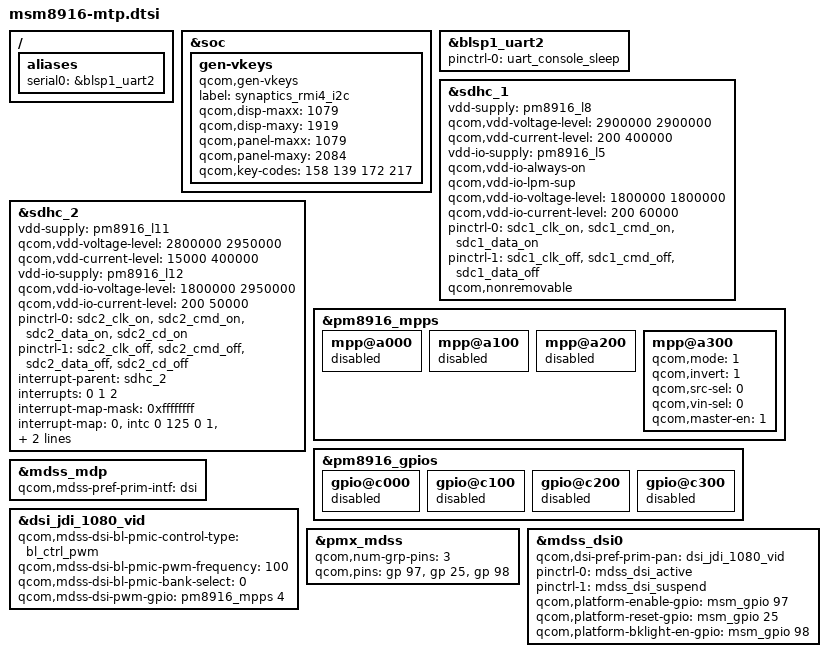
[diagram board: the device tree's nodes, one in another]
/* Copyright (c) 2014, The Linux Foundation. All rights reserved.
 *
 * This program is free software; you can redistribute it and/or modify
 * it under the terms of the GNU General Public License version 2 and
 * only version 2 as published by the Free Software Foundation.
 *
 * This program is distributed in the hope that it will be useful,
 * but WITHOUT ANY WARRANTY; without even the implied warranty of
 * MERCHANTABILITY or FITNESS FOR A PARTICULAR PURPOSE.  See the
 * GNU General Public License for more details.
 */

#include "msm8916.dtsi"
#include "msm8916-pinctrl.dtsi"

/ {
	aliases {
		serial0 = &blsp1_uart2;
	};
};

&soc {
	gen-vkeys {
		compatible = "qcom,gen-vkeys";
		label = "synaptics_rmi4_i2c";
		qcom,disp-maxx = <1079>;
		qcom,disp-maxy = <1919>;
		qcom,panel-maxx = <1079>;
		qcom,panel-maxy = <2084>;
		qcom,key-codes = <158 139 172 217>;
	};
};

&blsp1_uart2 {
	status = "ok";
	pinctrl-names = "default";
	pinctrl-0 = <&uart_console_sleep>;
};

&sdhc_1 {
	vdd-supply = <&pm8916_l8>;
	qcom,vdd-voltage-level = <2900000 2900000>;
	qcom,vdd-current-level = <200 400000>;

	vdd-io-supply = <&pm8916_l5>;
	qcom,vdd-io-always-on;
	qcom,vdd-io-lpm-sup;
	qcom,vdd-io-voltage-level = <1800000 1800000>;
	qcom,vdd-io-current-level = <200 60000>;

	pinctrl-names = "active", "sleep";
	pinctrl-0 = <&sdc1_clk_on &sdc1_cmd_on &sdc1_data_on>;
	pinctrl-1 = <&sdc1_clk_off &sdc1_cmd_off &sdc1_data_off>;

	qcom,nonremovable;

	status = "ok";
};

&sdhc_2 {
	vdd-supply = <&pm8916_l11>;
	qcom,vdd-voltage-level = <2800000 2950000>;
	qcom,vdd-current-level = <15000 400000>;

	vdd-io-supply = <&pm8916_l12>;
	qcom,vdd-io-voltage-level = <1800000 2950000>;
	qcom,vdd-io-current-level = <200 50000>;

	pinctrl-names = "active", "sleep";
	pinctrl-0 = <&sdc2_clk_on &sdc2_cmd_on &sdc2_data_on &sdc2_cd_on>;
	pinctrl-1 = <&sdc2_clk_off &sdc2_cmd_off &sdc2_data_off &sdc2_cd_off>;

	#address-cells = <0>;
	interrupt-parent = <&sdhc_2>;
	interrupts = <0 1 2>;
	#interrupt-cells = <1>;
	interrupt-map-mask = <0xffffffff>;
	interrupt-map = <0 &intc 0 125 0
			1 &intc 0 221 0
			2 &msm_gpio 38 0>;
	interrupt-names = "hc_irq", "pwr_irq", "status_irq";
	cd-gpios = <&msm_gpio 38 0x1>;

	status = "ok";
};

&pm8916_mpps {
	mpp@a000 { /* MPP 1 */
		/* VDD_PX */
		status = "disabled";
	};

	mpp@a100 { /* MPP 2 */
		/* HR LED */
		status = "disabled";
	};

	mpp@a200 { /* MPP 3 */
		/* VREF DAC */
		status = "disabled";
	};

	mpp@a300 { /* MPP 4 */
		/* Backlight PWM */
		qcom,mode = <1>;		/* Digital output */
		qcom,invert = <1>;		/* Output high initially */
		qcom,src-sel = <0>;		/* Constant */
		qcom,vin-sel = <0>;		/* VPH_PWR */
		qcom,master-en = <1>;		/* Enable MPP */
	};
};

&pm8916_gpios {
	gpio@c000 { /* GPIO 1 */
		/* Battery UICC Alarm */
		status = "disabled";
	};

	gpio@c100 { /* GPIO 2 */
		/* NFC_CLK */
		status = "disabled";
	};

	gpio@c200 { /* GPIO 3 */
		/* External regulator control for WTR */
		status = "disabled";
	};

	gpio@c300 { /* GPIO 4 */
		/* External regulator control for APC */
		status = "disabled";
	};
};

#include "dsi-panel-jdi-1080p-video.dtsi"

&mdss_mdp {
	qcom,mdss-pref-prim-intf = "dsi";
};

&dsi_jdi_1080_vid {
	qcom,mdss-dsi-bl-pmic-control-type = "bl_ctrl_pwm";
	qcom,mdss-dsi-bl-pmic-pwm-frequency = <100>;
	qcom,mdss-dsi-bl-pmic-bank-select = <0>;
	qcom,mdss-dsi-pwm-gpio = <&pm8916_mpps 4 0>;

};

&pmx_mdss {
	qcom,num-grp-pins = <3>;
	qcom,pins = <&gp 97>, <&gp 25>, <&gp 98>;
};

&mdss_dsi0 {
	qcom,dsi-pref-prim-pan = <&dsi_jdi_1080_vid>;
	pinctrl-names = "mdss_default", "mdss_sleep";
	pinctrl-0 = <&mdss_dsi_active>;
	pinctrl-1 = <&mdss_dsi_suspend>;

	qcom,platform-enable-gpio = <&msm_gpio 97 0>;
	qcom,platform-reset-gpio = <&msm_gpio 25 0>;
	qcom,platform-bklight-en-gpio = <&msm_gpio 98 0>;
};
